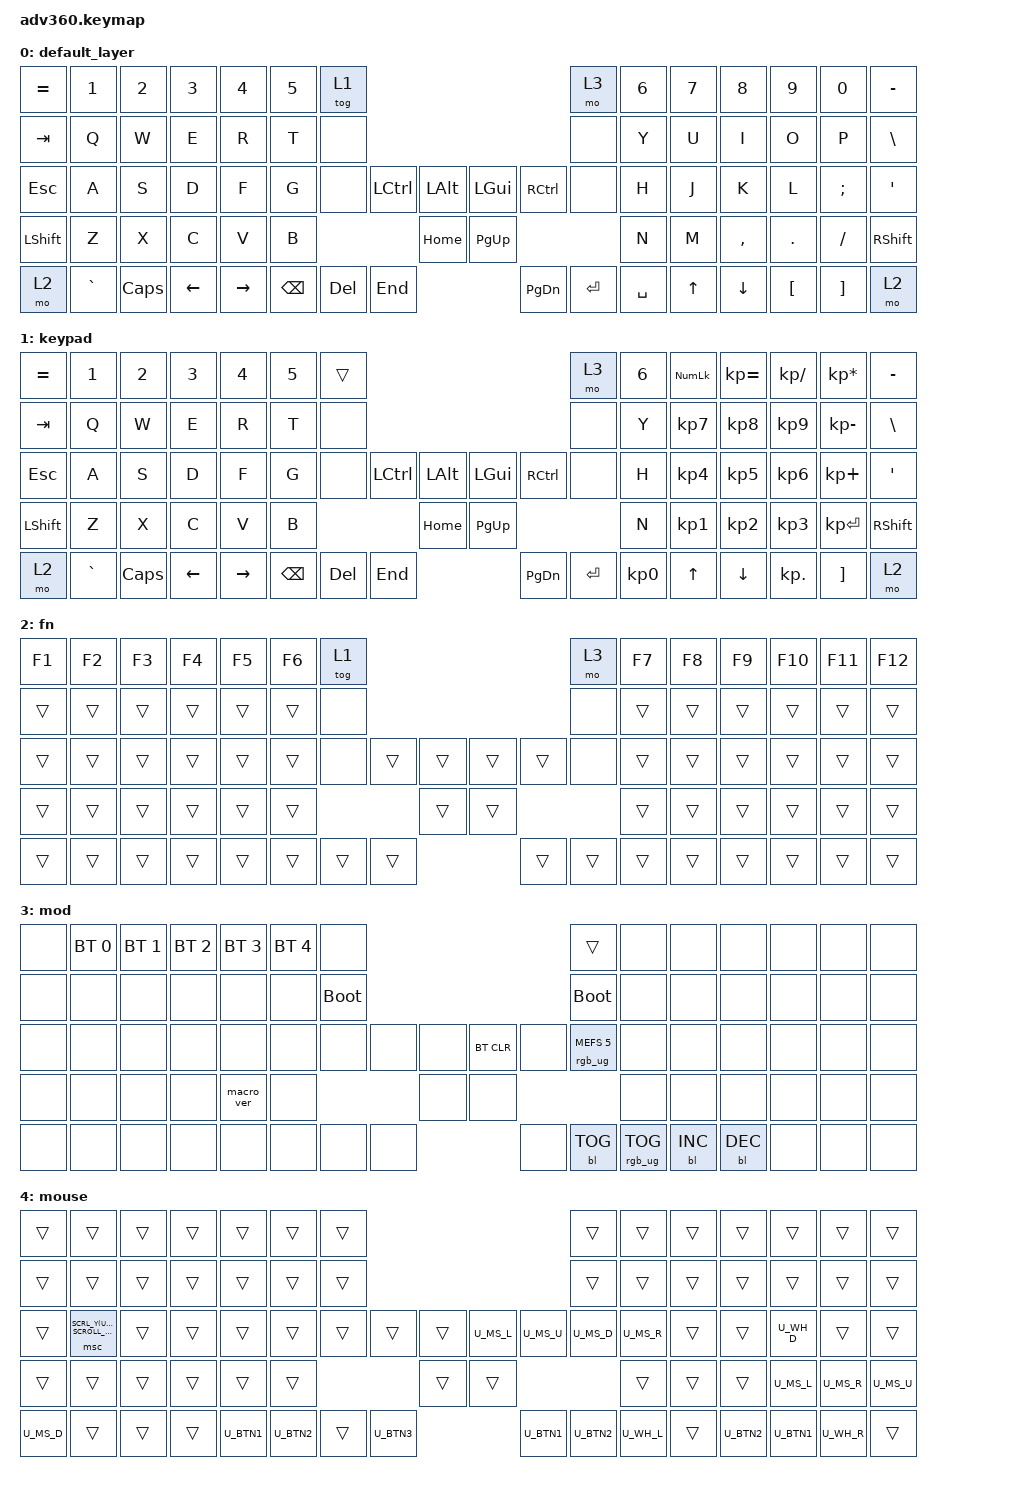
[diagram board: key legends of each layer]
#include <behaviors.dtsi>
#include <dt-bindings/zmk/keys.h>
#include <dt-bindings/zmk/bt.h>
#include <dt-bindings/zmk/rgb.h>
#include <dt-bindings/zmk/backlight.h>
#include "mouse.dtsi"
#define ___ &trans
/ {
    behaviors {
      #include "macros.dtsi"
      #include "version.dtsi"
      #ifndef VERSION_MACRO
      macro_ver: macro_ver {
        compatible = "zmk,behavior-macro";
        label = "macro_version";
        #binding-cells = <0>;
        bindings = <&kp RET>;
      };
      #endif

      hm: homerow_mods {
          compatible = "zmk,behavior-hold-tap";
          label = "HOMEROW_MODS";
          #binding-cells = <2>;
          tapping-term-ms = <200>;
          quick_tap_ms = <175>;
          flavor = "tap-preferred";
          bindings = <&kp>, <&kp>;
      };
    };

  keymap {
    compatible = "zmk,keymap";

    default_layer {
      bindings = <
        &kp EQUAL &kp N1    &kp N2   &kp N3   &kp N4     &kp N5 &tog 1                                                           &mo 3 &kp N6 &kp N7 &kp N8    &kp N9   &kp N0   &kp MINUS
        &kp TAB   &kp Q     &kp W    &kp E    &kp R      &kp T  &none                                                            &none &kp Y  &kp U  &kp I     &kp O    &kp P    &kp BSLH
        &kp ESC   &kp A     &kp S    &kp D    &kp F      &kp G  &none           &kp LCTRL &kp LALT &kp LGUI  &kp RCTRL           &none &kp H  &kp J  &kp K     &kp L    &kp SEMI &kp SQT
        &kp LSHFT &kp Z     &kp X    &kp C    &kp V      &kp B                            &kp HOME &kp PG_UP                           &kp N  &kp M  &kp COMMA &kp DOT  &kp FSLH &kp RSHFT
        &mo 2     &kp GRAVE &kp CAPS &kp LEFT &kp RIGHT                &kp BSPC &kp DEL   &kp END  &kp PG_DN &kp ENTER &kp SPACE              &kp UP &kp DOWN  &kp LBKT &kp RBKT &mo 2
      >;
    };
    keypad {
      bindings = <
        &kp EQUAL &kp N1    &kp N2   &kp N3   &kp N4     &kp N5 &trans                                                           &mo 3 &kp N6 &kp KP_NUM &kp KP_EQUAL &kp KP_DIVIDE &kp KP_MULTIPLY &kp MINUS
        &kp TAB   &kp Q     &kp W    &kp E    &kp R      &kp T  &none                                                            &none &kp Y  &kp KP_N7  &kp KP_N8    &kp KP_N9     &kp KP_MINUS    &kp BSLH
        &kp ESC   &kp A     &kp S    &kp D    &kp F      &kp G  &none           &kp LCTRL &kp LALT &kp LGUI  &kp RCTRL           &none &kp H  &kp KP_N4  &kp KP_N5    &kp KP_N6     &kp KP_PLUS     &kp SQT
        &kp LSHFT &kp Z     &kp X    &kp C    &kp V      &kp B                            &kp HOME &kp PG_UP                           &kp N  &kp KP_N1  &kp KP_N2    &kp KP_N3     &kp KP_ENTER    &kp RSHFT
        &mo 2     &kp GRAVE &kp CAPS &kp LEFT &kp RIGHT                &kp BSPC &kp DEL   &kp END  &kp PG_DN &kp ENTER &kp KP_N0              &kp UP     &kp DOWN     &kp KP_DOT    &kp RBKT        &mo 2
      >;
    };
    fn {
      bindings = <
        &kp F1 &kp F2 &kp F3 &kp F4 &kp F5 &kp F6 &tog 1                                           &mo 3 &kp F7 &kp F8 &kp F9 &kp F10 &kp F11 &kp F12
        &trans &trans &trans &trans &trans &trans  &none                                           &none &trans &trans &trans &trans  &trans  &trans
        &trans &trans &trans &trans &trans &trans  &none        &trans &trans &trans &trans        &none &trans &trans &trans &trans  &trans  &trans
        &trans &trans &trans &trans &trans &trans                      &trans &trans                     &trans &trans &trans &trans  &trans  &trans
        &trans &trans &trans &trans &trans               &trans &trans &trans &trans &trans &trans              &trans &trans &trans  &trans  &trans
      >;
    };
    mod {
      bindings = <
        &none &bt BT_SEL 0 &bt BT_SEL 1 &bt BT_SEL 2 &bt BT_SEL 3 &bt BT_SEL 4 &none                                                                     &trans                 &none        &none        &none        &none &none &none
        &none &none        &none        &none        &none        &none        &bootloader                                                               &bootloader            &none        &none        &none        &none &none &none
        &none &none        &none        &none        &none        &none        &none                   &none &none &bt BT_CLR &none                      &rgb_ug RGB_MEFS_CMD 5 &none        &none        &none        &none &none &none
        &none &none        &none        &none        &macro_ver   &none                                      &none &none                                                        &none        &none        &none        &none &none &none
        &none &none        &none        &none        &none                                       &none &none &none &none      &bl BL_TOG &rgb_ug RGB_TOG                                     &bl BL_INC   &bl BL_DEC   &none &none &none
      >;
    };
       mouse {
           bindings = <
               ___       ___       ___       ___       ___       ___       ___            ___       ___       ___       ___       ___       ___       ___
               ___       ___       ___       ___       ___       ___       ___            ___       ___       ___       ___       ___       ___       ___
               ___       &msc SCRL_Y(U_MOUSE_SCROLL_MAX)    ___       ___       ___       ___       ___            ___       ___       U_MS_L    U_MS_U    U_MS_D    U_MS_R    ___
               ___       U_WH_D    ___       ___       ___       ___                                ___       ___       ___       ___       ___       ___
               ___       ___       ___       U_MS_L    U_MS_R                                                 U_MS_U    U_MS_D    ___       ___       ___
                                                                 U_BTN1    U_BTN2         ___       U_BTN3
                                                       U_BTN1    U_BTN2    U_WH_L         ___       U_BTN2    U_BTN1
                                                                           U_WH_R         ___
           >;
       };
    }
  };
};
